# HC32K116 register map
File version: 1.0
CPU: CM0+ r0p1, little endian, no MPU, no FPU, 2 interrupt priority bits
Registers are 32-bit, read-write, reset 0x0 unless marked. A register's access mark holds for its fields unless they carry their own. Offsets are from the block's base; [hi:lo] are bit positions; {n}, {i} and the like mark numbered series; 'fields as' and 'values as' point back to an identical list.

## RMU
Base 0x40014100
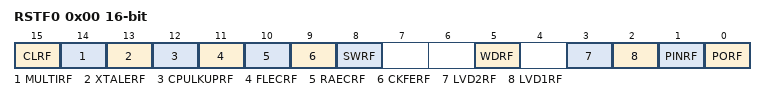
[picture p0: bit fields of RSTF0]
0x00 RSTF0 16-bit
  [15] CLRF, [14] MULTIRF, [13] XTALERF, [12] CPULKUPRF, [11] FLECRF, [10] RAECRF, [9] CKFERF, [8] SWRF, [5] WDRF, [3] LVD2RF, [2] LVD1RF, [1] PINRF, [0] PORF

## RTC
Base 0x4000D400
0x00 CR0 8-bit
  [0] RESET
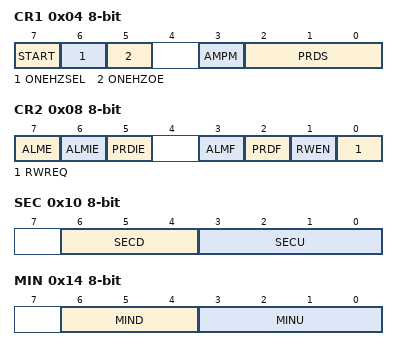
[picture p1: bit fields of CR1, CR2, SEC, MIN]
0x04 CR1 8-bit
  [7] START, [6] ONEHZSEL, [5] ONEHZOE, [3] AMPM, [2:0] PRDS
0x08 CR2 8-bit
  [7] ALME, [6] ALMIE, [5] PRDIE, [3] ALMF, [2] PRDF, [1] RWEN, [0] RWREQ
0x0C CR3 8-bit
  [7:6] RCKSEL
0x10 SEC 8-bit
  [6:4] SECD, [3:0] SECU
0x14 MIN 8-bit
  [6:4] MIND, [3:0] MINU
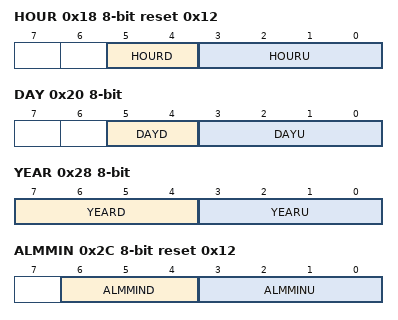
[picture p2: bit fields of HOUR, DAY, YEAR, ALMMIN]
0x18 HOUR 8-bit reset 0x12
  [5:4] HOURD, [3:0] HOURU
0x1C WEEK 8-bit
  [2:0] WEEK
0x20 DAY 8-bit
  [5:4] DAYD, [3:0] DAYU
0x24 MON 8-bit
  [4:0] MON
0x28 YEAR 8-bit
  [7:4] YEARD, [3:0] YEARU
0x2C ALMMIN 8-bit reset 0x12
  [6:4] ALMMIND, [3:0] ALMMINU
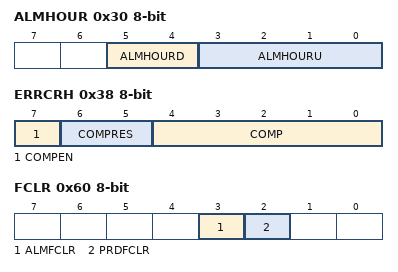
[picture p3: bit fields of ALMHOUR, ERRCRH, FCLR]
0x30 ALMHOUR 8-bit
  [5:4] ALMHOURD, [3:0] ALMHOURU
0x34 ALMWEEK 8-bit
  [6:0] ALMWEEK
0x38 ERRCRH 8-bit
  [7] COMPEN, [6:5] COMPRES, [4:0] COMP
0x3C ERRCRL 8-bit reset 0x20
0x60 FCLR 8-bit
  [3] ALMFCLR, [2] PRDFCLR

## SPI1 — desc SPI
Base 0x40003800
Same registers: SPI2 0x40003C00
0x00 DR
  [15:0] SPD
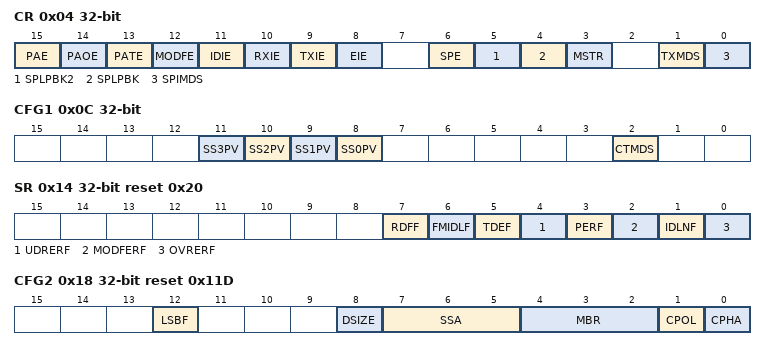
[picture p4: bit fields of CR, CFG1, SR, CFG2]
0x04 CR
  [15] PAE, [14] PAOE, [13] PATE, [12] MODFE, [11] IDIE, [10] RXIE, [9] TXIE, [8] EIE, [6] SPE, [5] SPLPBK2, [4] SPLPBK, [3] MSTR, [1] TXMDS, [0] SPIMDS
0x0C CFG1
  [n+8] SS{n}PV (n=0..3), [2] CTMDS
0x14 SR reset 0x20
  [7] RDFF ro, [6] FMIDLF ro, [5] TDEF ro, [4] UDRERF, [3] PERF, [2] MODFERF, [1] IDLNF ro, [0] OVRERF
0x18 CFG2 reset 0x11D
  [12] LSBF, [8] DSIZE, [7:5] SSA, [4:2] MBR, [1] CPOL, [0] CPHA

## SRAMC
Base 0x40010C00
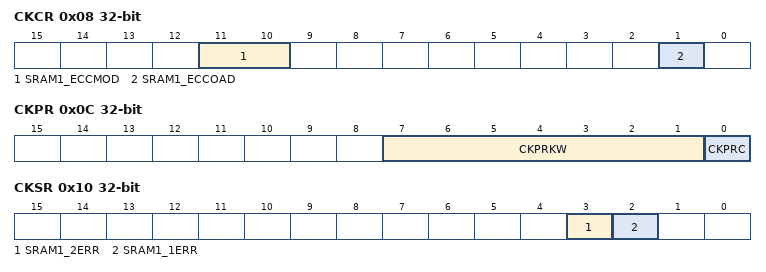
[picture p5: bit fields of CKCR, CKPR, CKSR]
0x08 CKCR
  [11:10] SRAM1_ECCMOD, [1] SRAM1_ECCOAD
0x0C CKPR
  [7:1] CKPRKW, [0] CKPRC
0x10 CKSR
  [3] SRAM1_2ERR, [2] SRAM1_1ERR
0x14 SRAM1_EIEN
  [0] EIEN
0x18 SRAM1_EIBIT0
0x1C SRAM1_EIBIT1
  [6:0] EIBIT
0x20 SRAM1_ECCERRADDR
  [16:0] ECCERRADDR

## SWDT
Base 0x4000CC00
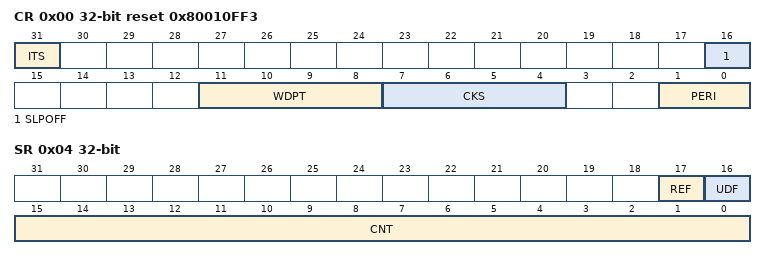
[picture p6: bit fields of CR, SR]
0x00 CR reset 0x80010FF3
  [31] ITS, [16] SLPOFF, [11:8] WDPT, [7:4] CKS, [1:0] PERI
0x04 SR
  [17] REF, [16] UDF, [15:0] CNT ro
0x08 RR
  [15:0] RF

## TMR0
Base 0x40005800
0x00 CNTAR
  [15:0] CNTA
0x08 CMPAR reset 0xFFFF
  [15:0] CMPA
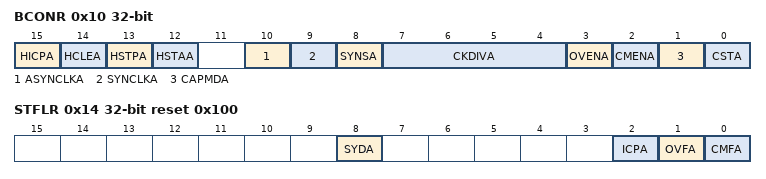
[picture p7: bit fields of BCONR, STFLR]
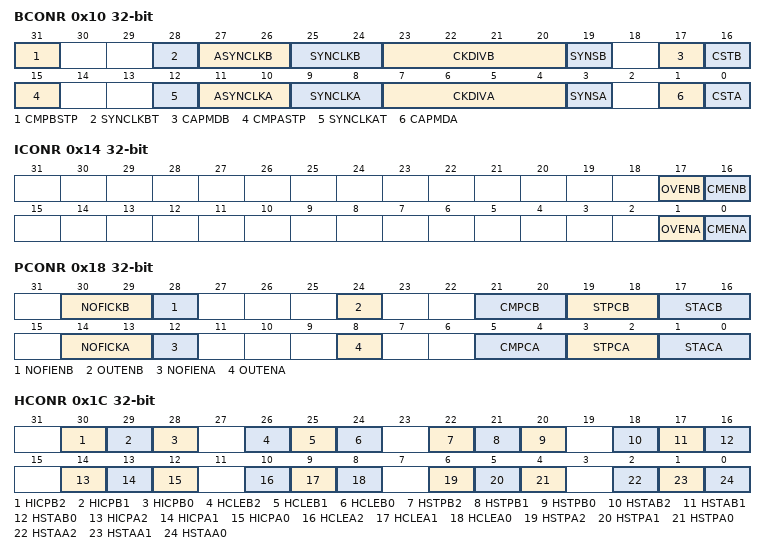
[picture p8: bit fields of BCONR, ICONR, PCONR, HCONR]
0x10 BCONR
  [15] HICPA, [14] HCLEA, [13] HSTPA, [12] HSTAA, [10] ASYNCLKA, [9] SYNCLKA, [8] SYNSA, [7:4] CKDIVA, [3] OVENA, [2] CMENA, [1] CAPMDA, [0] CSTA
0x14 STFLR reset 0x100
  [8] SYDA, [2] ICPA, [1] OVFA, [0] CMFA

## TMR21 — desc TMR2
Base 0x40005C00
Same registers: TMR22 0x40006000
0x00 CNTAR
  [15:0] CNTA
0x04 CNTBR
  [15:0] CNTB
0x08 CMPAR reset 0xFFFF
  [15:0] CMPA
0x0C CMPBR reset 0xFFFF
  [15:0] CMPB
0x10 BCONR
  [31] CMPBSTP, [28] SYNCLKBT, [27:26] ASYNCLKB, [25:24] SYNCLKB, [23:20] CKDIVB, [19] SYNSB, [17] CAPMDB, [16] CSTB, [15] CMPASTP, [12] SYNCLKAT, [11:10] ASYNCLKA, [9:8] SYNCLKA, [7:4] CKDIVA, [3] SYNSA, [1] CAPMDA, [0] CSTA
0x14 ICONR
  [17] OVENB, [16] CMENB, [1] OVENA, [0] CMENA
0x18 PCONR
  [30:29] NOFICKB, [28] NOFIENB, [24] OUTENB, [21:20] CMPCB, [19:18] STPCB, [17:16] STACB, [14:13] NOFICKA, [12] NOFIENA, [8] OUTENA, [5:4] CMPCA, [3:2] STPCA, [1:0] STACA
0x1C HCONR
  [30] HICPB2, [29] HICPB1, [28] HICPB0, [26] HCLEB2, [25] HCLEB1, [24] HCLEB0, [22] HSTPB2, [21] HSTPB1, [20] HSTPB0, [18] HSTAB2, [17] HSTAB1, [16] HSTAB0, [14] HICPA2, [13] HICPA1, [12] HICPA0, [10] HCLEA2, [9] HCLEA1, [8] HCLEA0, [6] HSTPA2, [5] HSTPA1, [4] HSTPA0, [2] HSTAA2, [1] HSTAA1, [0] HSTAA0
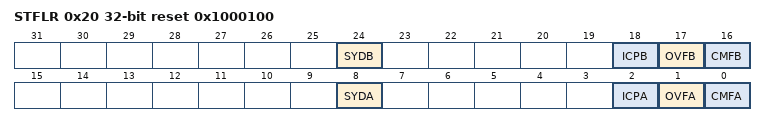
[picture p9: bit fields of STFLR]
0x20 STFLR reset 0x1000100
  [24] SYDB, [18] ICPB, [17] OVFB, [16] CMFB, [8] SYDA, [2] ICPA, [1] OVFA, [0] CMFA

## TMR4
Base 0x40006800
0x00 OCCRUH 16-bit
0x04 OCCRUL 16-bit
0x08 OCCRVH 16-bit
0x0C OCCRVL 16-bit
0x10 OCCRWH 16-bit
0x14 OCCRWL 16-bit
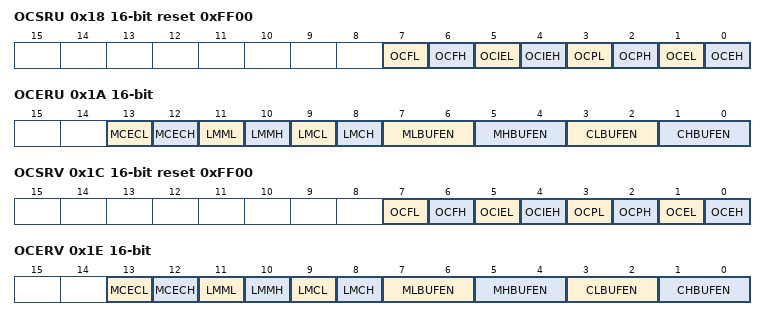
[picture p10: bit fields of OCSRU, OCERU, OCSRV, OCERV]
0x18 OCSRU 16-bit reset 0xFF00
  [7] OCFL, [6] OCFH, [5] OCIEL, [4] OCIEH, [3] OCPL, [2] OCPH, [1] OCEL, [0] OCEH
0x1A OCERU 16-bit
  [13] MCECL, [12] MCECH, [11] LMML, [10] LMMH, [9] LMCL, [8] LMCH, [7:6] MLBUFEN, [5:4] MHBUFEN, [3:2] CLBUFEN, [1:0] CHBUFEN
0x1C OCSRV 16-bit reset 0xFF00
  fields as OCSRU
0x1E OCERV 16-bit
  fields as OCERU
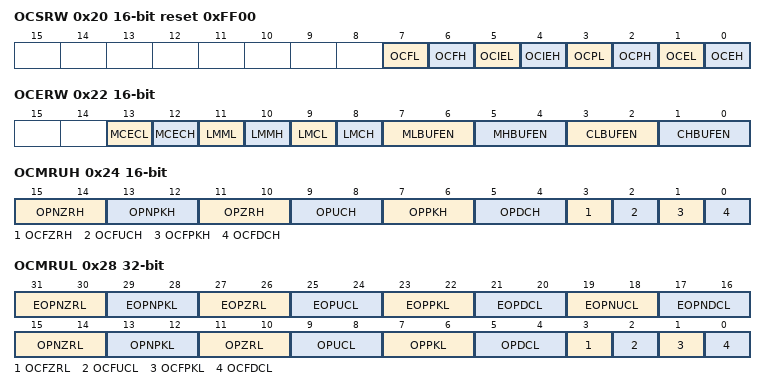
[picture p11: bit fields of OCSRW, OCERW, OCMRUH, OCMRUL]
0x20 OCSRW 16-bit reset 0xFF00
  fields as OCSRU
0x22 OCERW 16-bit
  fields as OCERU
0x24 OCMRUH 16-bit
  [15:14] OPNZRH, [13:12] OPNPKH, [11:10] OPZRH, [9:8] OPUCH, [7:6] OPPKH, [5:4] OPDCH, [3] OCFZRH, [2] OCFUCH, [1] OCFPKH, [0] OCFDCH
0x28 OCMRUL
  [31:30] EOPNZRL, [29:28] EOPNPKL, [27:26] EOPZRL, [25:24] EOPUCL, [23:22] EOPPKL, [21:20] EOPDCL, [19:18] EOPNUCL, [17:16] EOPNDCL, [15:14] OPNZRL, [13:12] OPNPKL, [11:10] OPZRL, [9:8] OPUCL, [7:6] OPPKL, [5:4] OPDCL, [3] OCFZRL, [2] OCFUCL, [1] OCFPKL, [0] OCFDCL
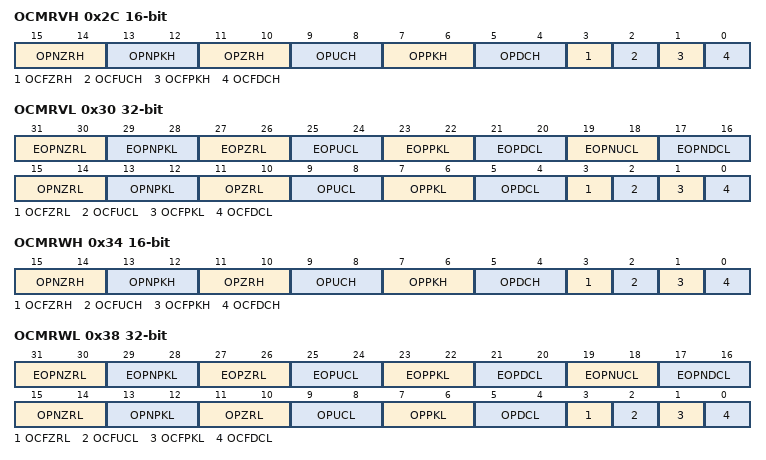
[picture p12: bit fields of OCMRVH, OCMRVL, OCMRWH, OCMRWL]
0x2C OCMRVH 16-bit
  fields as OCMRUH
0x30 OCMRVL
  fields as OCMRUL
0x34 OCMRWH 16-bit
  fields as OCMRUH
0x38 OCMRWL
  fields as OCMRUL
0x40 CPSR 16-bit reset 0xFFFF
0x44 CNTR 16-bit
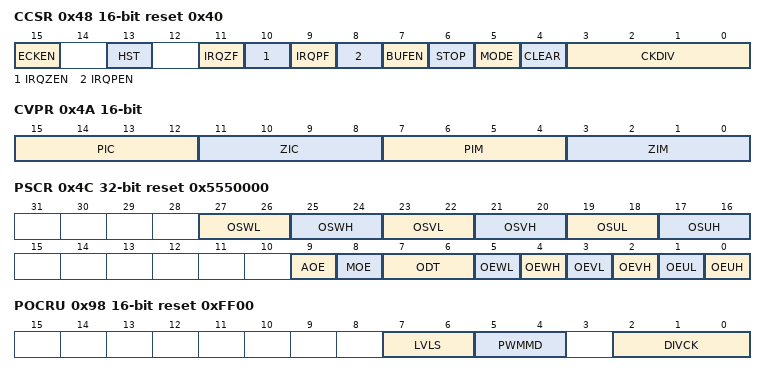
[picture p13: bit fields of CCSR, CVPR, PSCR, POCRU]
0x48 CCSR 16-bit reset 0x40
  [15] ECKEN, [13] HST, [11] IRQZF, [10] IRQZEN, [9] IRQPF, [8] IRQPEN, [7] BUFEN, [6] STOP, [5] MODE, [4] CLEAR, [3:0] CKDIV
0x4A CVPR 16-bit
  [15:12] PIC ro, [11:8] ZIC ro, [7:4] PIM, [3:0] ZIM
0x4C PSCR reset 0x5550000
  [27:26] OSWL, [25:24] OSWH, [23:22] OSVL, [21:20] OSVH, [19:18] OSUL, [17:16] OSUH, [9] AOE, [8] MOE, [7:6] ODT, [5] OEWL, [4] OEWH, [3] OEVL, [2] OEVH, [1] OEUL, [0] OEUH
0x82 PFSRU 16-bit
0x84 PDARU 16-bit
0x86 PDBRU 16-bit
0x8A PFSRV 16-bit
0x8C PDARV 16-bit
0x8E PDBRV 16-bit
0x92 PFSRW 16-bit
0x94 PDARW 16-bit
0x96 PDBRW 16-bit
0x98 POCRU 16-bit reset 0xFF00
  [7:6] LVLS, [5:4] PWMMD, [2:0] DIVCK
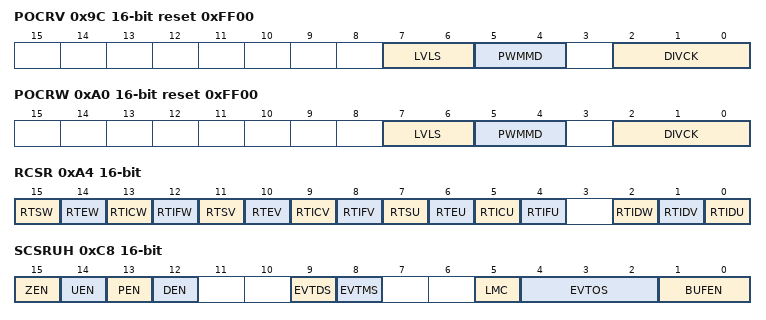
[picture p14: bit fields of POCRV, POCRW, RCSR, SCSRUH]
0x9C POCRV 16-bit reset 0xFF00
  [7:6] LVLS, [5:4] PWMMD, [2:0] DIVCK
0xA0 POCRW 16-bit reset 0xFF00
  [7:6] LVLS, [5:4] PWMMD, [2:0] DIVCK
0xA4 RCSR 16-bit
  [15] RTSW, [14] RTEW, [13] RTICW, [12] RTIFW ro, [11] RTSV, [10] RTEV, [9] RTICV, [8] RTIFV ro, [7] RTSU, [6] RTEU, [5] RTICU, [4] RTIFU ro, [2] RTIDW, [1] RTIDV, [0] RTIDU
0xB0 SCCRUH 16-bit
0xB4 SCCRUL 16-bit
0xB8 SCCRVH 16-bit
0xBC SCCRVL 16-bit
0xC0 SCCRWH 16-bit
0xC4 SCCRWL 16-bit
0xC8 SCSRUH 16-bit
  [15] ZEN, [14] UEN, [13] PEN, [12] DEN, [9] EVTDS, [8] EVTMS, [5] LMC, [4:2] EVTOS, [1:0] BUFEN
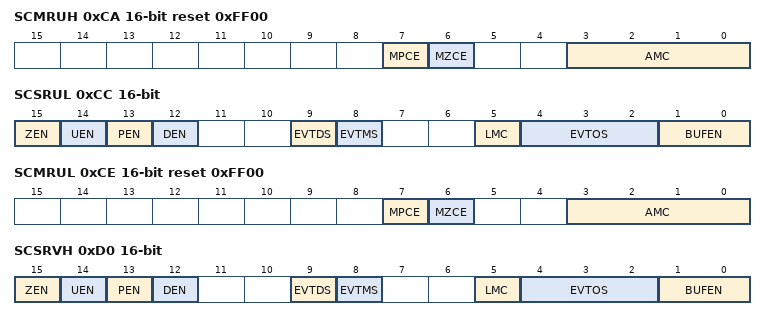
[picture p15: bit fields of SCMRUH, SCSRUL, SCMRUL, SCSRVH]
0xCA SCMRUH 16-bit reset 0xFF00
  [7] MPCE, [6] MZCE, [3:0] AMC
0xCC SCSRUL 16-bit
  fields as SCSRUH
0xCE SCMRUL 16-bit reset 0xFF00
  [7] MPCE, [6] MZCE, [3:0] AMC
0xD0 SCSRVH 16-bit
  fields as SCSRUH
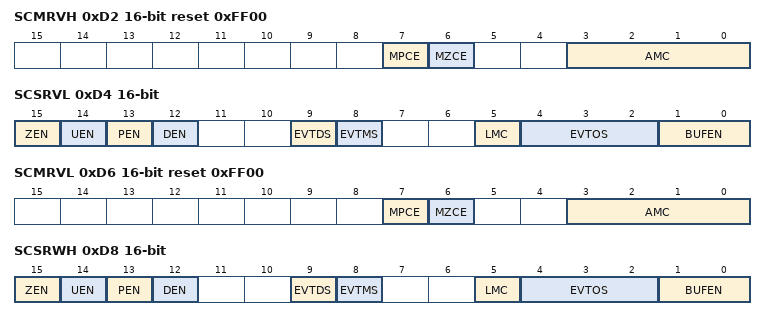
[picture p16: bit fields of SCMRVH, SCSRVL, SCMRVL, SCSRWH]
0xD2 SCMRVH 16-bit reset 0xFF00
  [7] MPCE, [6] MZCE, [3:0] AMC
0xD4 SCSRVL 16-bit
  fields as SCSRUH
0xD6 SCMRVL 16-bit reset 0xFF00
  [7] MPCE, [6] MZCE, [3:0] AMC
0xD8 SCSRWH 16-bit
  fields as SCSRUH
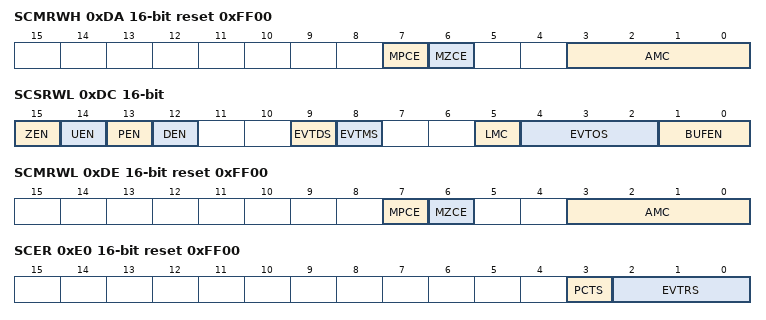
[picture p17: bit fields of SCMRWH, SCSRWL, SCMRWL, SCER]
0xDA SCMRWH 16-bit reset 0xFF00
  [7] MPCE, [6] MZCE, [3:0] AMC
0xDC SCSRWL 16-bit
  fields as SCSRUH
0xDE SCMRWL 16-bit reset 0xFF00
  [7] MPCE, [6] MZCE, [3:0] AMC
0xE0 SCER 16-bit reset 0xFF00
  [3] PCTS, [2:0] EVTRS
0xE4 SCIR 16-bit reset 0xFF00
  [n] ITEN{n} (n=0..5)
0xE8 SCFR 16-bit reset 0xFF00
  [n] SF{n} (n=0..5)

## TMRA
Base 0x40007000
0x00 CNTER 16-bit
0x04 PERAR 16-bit reset 0xFFFF
{0x3C+4i} CMPAR{i} 16-bit reset 0xFFFF (i=1..8)
0x80 BCSTRL 8-bit reset 0x2
  [7:4] CKDIV, [2] MODE, [1] DIR, [0] START
0x81 BCSTRH 8-bit
  [7] UDFF, [6] OVFF, [5] ITENUDF, [4] ITENOVF, [0] OVSTP
0x84 HCONR 16-bit
  [15] HCLE4, [14] HCLE3, [10] HCLE2, [9] HCLE1, [8] HCLE0, [6] HSTP2, [5] HSTP1, [4] HSTP0, [2] HSTA2, [1] HSTA1, [0] HSTA0
0x88 HCUPR 16-bit
  [n] HCUP{n} (n=0..10)
0x8C HCDOR 16-bit
  [n] HCDO{n} (n=0..10)
0x90 ICONR 16-bit
  [n-1] ITEN{n} (n=1..8)
0x94 ECONR 16-bit
  [n-1] ETEN{n} (n=1..8)
0x98 FCONR 16-bit
  [14:13] NOFICKCB, [12] NOFIENCB, [10:9] NOFICKCA, [8] NOFIENCA, [2:1] NOFICKTG, [0] NOFIENTG
0x9C STFLR 16-bit
  [n+7] ICPF{n} (n=1..8), [n-1] CMPF{n} (n=1..8)
{0xB8+8i} BCONR{i} 16-bit (i=1..4)
  [2] BSE1, [1] BSE0, [0] BEN
{0xFC+4i} CCONR{i} 16-bit (i=1..8)
  [14:13] NOFICKCP, [12] NOFIENCP, [n+5] HICP{n} (n=3..6), [6] HICP2, [5] HICP1, [4] HICP0, [0] CAPMD
{0x13C+4i} PCONR{i} 16-bit (i=1..8)
  [12] OUTEN, [9:8] FORC, [7:6] PERC, [5:4] CMPC, [3:2] STPC, [1:0] STAC

## USART1 — desc USART
Base 0x40001800
Same registers: USART2 0x40001C00
0x00 SR ro reset 0xC0
  [16] MPB, [11] TEND, [8] RTOF, [7] TXE, [6] TC, [5] RXNE, [3] ORE, [1] FE, [0] PE
0x04 TDR 16-bit reset 0x1FF
  [9] MPID, [8:0] TDR
0x06 RDR 16-bit ro
  [8:0] RDR
0x08 BRR reset 0xFFFF
  [15:8] DIV_INTEGER, [6:0] DIV_FRACTION
0x0C CR1 reset 0x80000000
  [31] SBS, [30] NFE, [29] FBME, [28] ML, [25] CTEND, [24] MS, [20] CRTOF, [19] CORE, [17] CFE, [16] CPE, [15] OVER8, [12] M, [10] PCE, [9] PS, [8] TENDIE, [7] TXEIE, [6] TCIE, [5] RIE, [4] SLME, [3] TE, [2] RE, [1] RTOIE, [0] RTOE
0x10 CR2 reset 0x600
  [13] STOP, [12:11] CLKC, [0] MPE
0x14 CR3
  [31] DEP, [30] DEM, [28:25] DEA, [23:21] BCN, [13:10] DED, [9] CTSE, [8] RTSE, [5] SCEN, [3] HDSEL
0x18 PR
  [11:8] RTOB, [4] ULBREN, [1:0] PSC

## USART3 — desc USART
Base 0x40002000
Same registers: USART4 0x40002400
0x00 SR ro reset 0xC0
  [16] MPB, [12] LBM, [11] TEND, [10] LBD, [9] WKUP, [8] RTOF, [7] TXE, [6] TC, [5] RXNE, [4] BE, [3] ORE, [1] FE, [0] PE
0x04 TDR 16-bit reset 0x1FF
  [9] MPID, [8:0] TDR
0x06 RDR 16-bit ro
  [8:0] RDR
0x08 BRR reset 0xFFFF
  [15:8] DIV_INTEGER, [6:0] DIV_FRACTION
0x0C CR1 reset 0x80000000
  [31] SBS, [30] NFE, [29] FBME, [28] ML, [26] CLBM, [25] CTEND, [24] MS, [23] CLBD, [22] CWKUP, [21] CBE, [20] CRTOF, [19] CORE, [17] CFE, [16] CPE, [15] OVER8, [12] M, [10] PCE, [9] PS, [8] TENDIE, [7] TXEIE, [6] TCIE, [5] RIE, [4] SLME, [3] TE, [2] RE, [1] RTOIE, [0] RTOE
0x10 CR2 reset 0x600
  [19] LBMIE, [17] SBKM, [16] SBK, [15] UATSBKE, [14] LINEN, [13] STOP, [12:11] CLKC, [8] WKUPE, [7:6] SBKL, [5] LBDL, [4] LBDIE, [3] BEE, [2] BEIE, [1] WKUPIE, [0] MPE
0x14 CR3
  [31] DEP, [30] DEM, [28:25] DEA, [13:10] DED, [9] CTSE, [8] RTSE, [4] LOOP, [3] HDSEL
0x18 PR
  [11:8] RTOB, [4] ULBREN, [3:2] LBMPSC, [1:0] PSC
0x1C LBMC ro
  [15:0] LBMC
